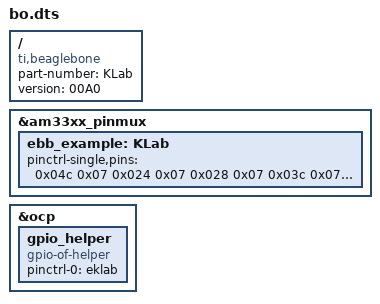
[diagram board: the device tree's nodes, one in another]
/*  
* Copyright (C) 2012 Texas Instruments Incorporated - http://www.ti.com/
*
* This program is free software; you can redistribute it and/or modify
* it under the terms of the GNU General Purpose License Version 2 as
* published by the Free Software Foundation
*
* Original from: github.com/jadonk/validation-scripts/blob/master/test-capemgr/ 
* 
* Modified by Fabio Busignani fbusigna@mit.edu
*
*/

/dts-v1/;
/plugin/;

/{
       compatible = "ti,beaglebone", "ti,beaglebone-black";
       part-number = "KLab";
       version = "00A0";

       fragment@0 {
             target = <&am33xx_pinmux>;
            
             __overlay__ {
                  ebb_example: KLab {
			pinctrl-single,pins = <
                                0x04c 0x07  // P9_16 - Temperture controller - Output Mode7 pulldown
                                0x024 0x07  // P8_13 - EV1 - Output Mode7 pulldown
                                0x028 0x07  // P8_14 - EV4 - Output Mode7 pulldown
                                0x03c 0x07  // P8_15 - EV3 - Output Mode7 pulldown
                                0x038 0x07  // P8_16 - EV6 - Output Mode7 pulldown
                                0x02c 0x07  // P8_17 - EV5 - Output Mode7 pulldown
                                0x08c 0x07  // P8_18 - EV8 - Output Mode7 pulldown
                                0x020 0x07  // P8_19 - EV7 - Output Mode7 pulldown
                                0x030 0x07  // P8_44 - EV2 -Output Mode7 pulldown
                                0x0a0 0x07  // P8_46 - PowerSupply
  
			>;
		  };
             };
       };

       fragment@1 {
		target = <&ocp>;
		__overlay__ {
			gpio_helper {
				compatible = "gpio-of-helper";
				status = "okay";
				pinctrl-names = "default";
				pinctrl-0 = <&eklab>;
			};
		};
	};
};
